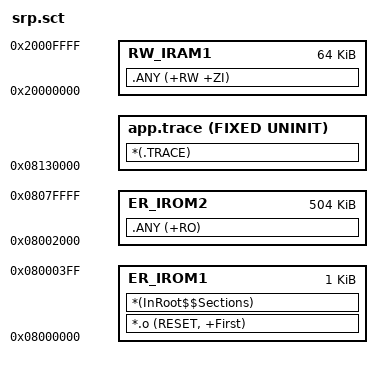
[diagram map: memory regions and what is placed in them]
; *************************************************************
; *** Scatter-Loading Description File generated by uVision ***
; *************************************************************

LR_IROM1 0x08000000 0x00001000  {    ; load region size_region
  ER_IROM1 0x08000000 0x00000400  {  ; load address = execution address
   *.o (RESET, +First)
   *(InRoot$$Sections)
  }
  RW_IRAM1 0x20000000 0x00010000  {  ; RW data
   .ANY (+RW +ZI)
  }
}

LR_IROM2 0x08002000 0x0007E000  {
  ER_IROM2 0x08002000 0x0007E000  {  ; load address = execution address
   .ANY (+RO)
  }
}

TRACE_DATA  0x08130000 0x10000
{
  app.trace 0x08130000 FIXED UNINIT
  {
    *(.TRACE)
  }
}
